# T113-S3 register map
Vendor: Allwinner; Series: T113-S3; File version: 0.1
CPU: other 0, little endian, MPU, no FPU, 0 interrupt priority bits
Registers are 32-bit, read-write, reset 0x0 unless marked. A register's access mark holds for its fields unless they carry their own. Offsets are from the block's base; [hi:lo] are bit positions.

## C0_CPUX_CFG
Base 0x09010000
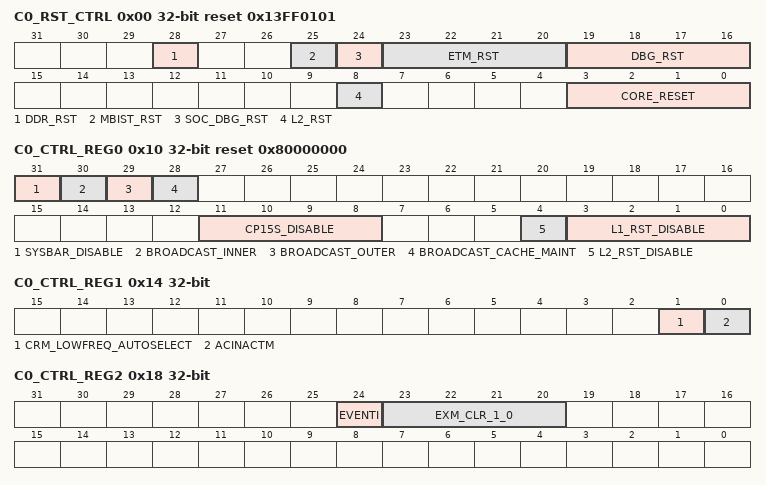
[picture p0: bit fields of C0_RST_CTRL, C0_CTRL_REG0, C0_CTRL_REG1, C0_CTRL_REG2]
0x00 C0_RST_CTRL reset 0x13FF0101 — Cluster 0 Reset Control Register
  [28] DDR_RST — AXI2MBUS Logic Circuit Reset 0: Assert 1: De-assert
    0=Assert; 1=deassert
  [25] MBIST_RST — CPUBIST Reset The reset signal is for test. 0: Assert 1: De-assert
    0=Assert; 1=deassert
  [24] SOC_DBG_RST — Cluster SoC Debug Reset 0: Assert 1: De-assert
    0=Assert; 1=deassert
  [23:20] ETM_RST — Cluster ETM Reset Assert 0: Assert 1: De-assert
  [19:16] DBG_RST — Cluster Debug Reset Assert 0: Assert 1: De-assert
  [8] L2_RST — Cluster L2 Cache Reset 0: Assert 1: De-assert
    0=Assert; 1=deassert
  [3:0] CORE_RESET — Cluster CPU[1:0] Reset Assert (The bit[3:2] is not used) 0: Assert 1: De-assert
0x10 C0_CTRL_REG0 reset 0x80000000 — Cluster 0 Control Register0
  [31] SYSBAR_DISABLE — Disable broadcasting barriers to the system bus. 0: Barriers are broadcasted to the system bus. This requires an AMBA4 interconnection. 1: Barriers are broadcasted to the system bus. This is compatible with an AXI3 interconnection.
    0=Barriers_are_broadcasted_to_the_system_bus_point__This_requires (Barriers are broadcasted to the system bus. This requires an AMBA4 interconnection.); 1=compatible (Barriers are broadcasted to the system bus. This is compatible with an AXI3 interconnection.)
  [30] BROADCAST_INNER — Enable broadcasting inner shareable transactions. 0: Inner shareable transactions are not broadcasted externally. 1: Inner shareable transactions are broadcasted externally.
    0=Inner shareable transactions are not broadcasted externally; 1=Inner shareable transactions are broadcasted externally
  [29] BROADCAST_OUTER — Enable broadcasting outer shareable transactions. 0: Outer Shareable transactions are not broadcasted externally. 0: Outer Shareable transactions are broadcasted externally.
    0=Outer Shareable transactions are not broadcasted externally; 0=Outer Shareable transactions are broadcasted externally
  [28] BROADCAST_CACHE_MAINT — Enable broadcasting cache maintenance operations to downstream caches. 0: Cache maintenance operations are not broadcasted to downstream caches. 1: Cache maintenance operations are broadcasted to downstream caches.
    0=Cache maintenance operations are not broadcasted to downstream caches; 1=Cache maintenance operations are broadcasted to downstream caches
  [11:8] CP15S_DISABLE — Disable write access to some secure CP15 registers The meaning of each bit: 0: Enable write access to CP15 register 1: Disable write access to CP15 register
  [4] L2_RST_DISABLE — Disable automatic L2 cache invalidation at reset. 0: L2 cache is reset by hardware. 1: L2 cache is not reset by hardware.
    0=reset (L2 cache is reset by hardware.); 1=not_reset (L2 cache is not reset by hardware.)
  [3:0] L1_RST_DISABLE — Disable automatic Cluster CPU[1:0] L1 cache invalidation at reset. (The bit[3:2] is not used) 0: L1 cache is reset by hardware. 1: L1 cache is not reset by hardware.
0x14 C0_CTRL_REG1 — Cluster 0 Control Register1
  [1] CRM_LOWFREQ_AUTOSELECT — Enable CRM to automatically select low frequency. 0: Disabled 1: Enabled
    0=Disabled; 1=Enabled
  [0] ACINACTM — Deactivate snoop interface 0: Snoop interface is active 1: Snoop interface is inactive and no longer accepts requests
    0=active (Snoop interface is active); 1=inactive (Snoop interface is inactive and no longer accepts requests)
0x18 C0_CTRL_REG2 — Cluster 0 Control Register2
  [24] EVENTI — Event input for processor to wake up from WFE state. This bit must remain high for at least one clock cycle to be visible by the cores.
  [23:20] EXM_CLR_1_0 — EXM_CLR[1:0] Clear the status of the corresponding interface. (The bit[23:22] is not used) The meaning of each bit: 0: Not to clear 1: Clear
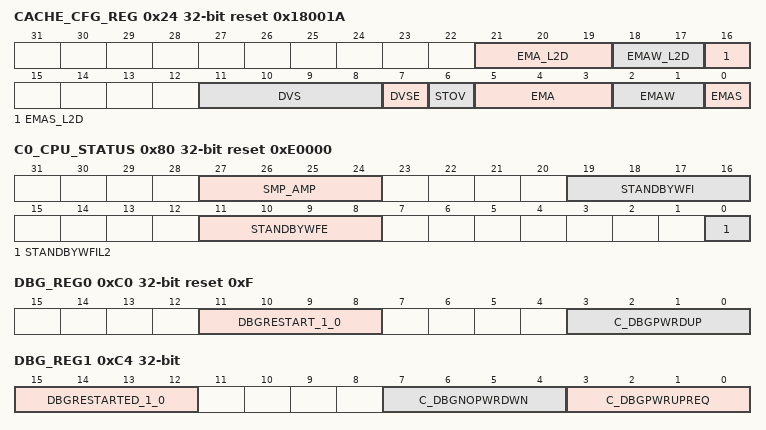
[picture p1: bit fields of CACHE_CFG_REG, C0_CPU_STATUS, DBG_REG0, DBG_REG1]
0x24 CACHE_CFG_REG reset 0x18001A — Cache Configuration Register Cluster0
  [21:19] EMA_L2D — Indicates the port number of L2 Cache SRAM EMA control port.
  [18:17] EMAW_L2D — Indicates the port number of L2 Cache SRAM EMAW control port.
  [16] EMAS_L2D — Indicates the port number of L2 Cache SRAM EMAS control port.
  [11:8] DVS — FARADAY SRAM delay signal
  [7] DVSE — FARADAY SRAM delay enable signal
  [6] STOV
  [5:3] EMA — Indicates the port number of Cache SRAM EMA control port.
  [2:1] EMAW — Indicates the port number of Cache SRAM EMAW control port.
  [0] EMAS — Indicates the port number of Cache SRAM EMAS control port.
0x80 C0_CPU_STATUS reset 0xE0000 — Cluster 0 CPU Status Register
  [27:24] SMP_AMP ro — Configure the operating mode for CPU[1:0] as Symmetric Multiprocessing mode or Asymmetric Multiprocessing mode. (The bit[27:26] is not used) 0: AMP mode 1: SMP mode
  [19:16] STANDBYWFI ro — Indicates if CPU[1:0] of Cluster0 is in WFI standby mode. (The bit[19:18] is not used) 0: The processor is not in WFI standby mode. 1: The processor is in WFI standby mode.
  [11:8] STANDBYWFE ro — Indicates if CPU[1:0] of Cluster0 is in the WFE standby mode. (The bit[11:10] is not used) 0: The processor is not in WFE standby mode. 1: The processor is in WFE standby mode.
  [0] STANDBYWFIL2 ro — Indicates if the L2 memory system of Cluster0 is in WFI standby mode. 0: Cluster0 L2 is not in WFI standby mode. 1: Cluster0 L2 is in WFI standby mode.
    0=not_in (Cluster0 L2 is not in WFI standby mode.); 1=in (Cluster0 L2 is in WFI standby mode.)
0x84 L2_STATUS_REG — Cluster 0 L2 Status Register
  [9] EVENTO ro — Event output. This bit is asserted high for 3 clock cycles when any core in the cluster executes an SEV instruction.
0xC0 DBG_REG0 reset 0xF — Cluster 0 Debug Control Register0
  [11:8] DBGRESTART_1_0 — DBGRESTART[1:0] Indicates if there are external restart requests for CPU[1:0]. (The bit[11:10] is not used) The meaning of each bit: 0: There are no such requests. 1: There are such requests.
  [3:0] C_DBGPWRDUP — Indicates if CPU[1:0] is powered-up. (The bit[3:2] is not used) The meaning of each bit: 0: The core is powered down. 1: The core is powered up.
0xC4 DBG_REG1 — Cluster 0 Debug Control Register1
  [15:12] DBGRESTARTED_1_0 — DBGRESTARTED[1:0] (The bit[15:14] is not used) Handshake for DBGRESTART.
  [7:4] C_DBGNOPWRDWN ro — Do Not Power Down Request. Indicates if the debugger requests CPU[1:0] not to power down. (The bit[7:6] is not used) The meaning of each bit: 0: There are no such requests. 1: There are such requests.
  [3:0] C_DBGPWRUPREQ ro — Power Up Request. Indicates if the debugger requests CPU[1:0] to power up. (The bit[3:2] is not used) The meaning of each bit: 0: There are no such requests. 1: There are such requests.
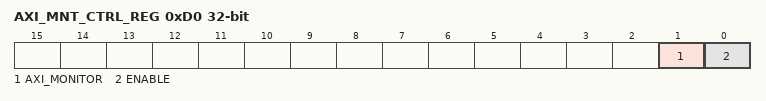
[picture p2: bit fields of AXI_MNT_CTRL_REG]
0xD0 AXI_MNT_CTRL_REG — AXI Monitor Control Register
  [1] AXI_MONITOR — function clear 0: Not to clear 1: Clear the AXI_MONITOR related registers with the offset address from 0x00D8 to 0x00EC.
    0=Not_to_clear; 1=Clear the AXI_MONITOR related registers with the offset address from 0x00D8 to 0x00EC
  [0] ENABLE — Enable AXI_MONITOR function 0: Disabled 1: Enabled
    0=Disabled; 1=Enabled
0xD4 AXI_MNT_PRD_REG — AXI Monitor Period Register
  [31:0] MONITORING — The monitoring period of AXI_MONITOR function (unit: cycles)
0xD8 AXI_MNT_RLTCY_REG — AXI Monitor Read Total Latency Register
  [31:0] TOTAL ro — The total latency of AXI_MONITOR function read channel (unit: cycles)
0xDC AXI_MNT_WLTCY_REG — AXI Monitor Write Total Latency Register
  [31:0] TOTAL ro — The total latency of AXI_MONITOR function write channel (unit: cycles)
0xE0 AXI_MNT_RREQ_REG — AXI Monitor Read Request Times Register
  [31:0] TOTAL ro — The total times of AXI_MONITOR function read channel requests.
0xE4 AXI_MNT_WREQ_REG — AXI Monitor Write Request Times Register
  [31:0] TOTAL ro — The total times of AXI_MONITOR function write channel requests.
0xE8 AXI_MNT_RBD_REG — AXI Monitor Read Bandwidth Register
  [31:0] BANDWIDTH ro — The bandwidth of AXI_MONITOR function read channel (Unit: KB)
0xEC AXI_MNT_WBD_REG — AXI Monitor Write Bandwidth Register
  [31:0] BANDWIDTH ro — The bandwidth of AXI_MONITOR function write channel (Unit: KB)
